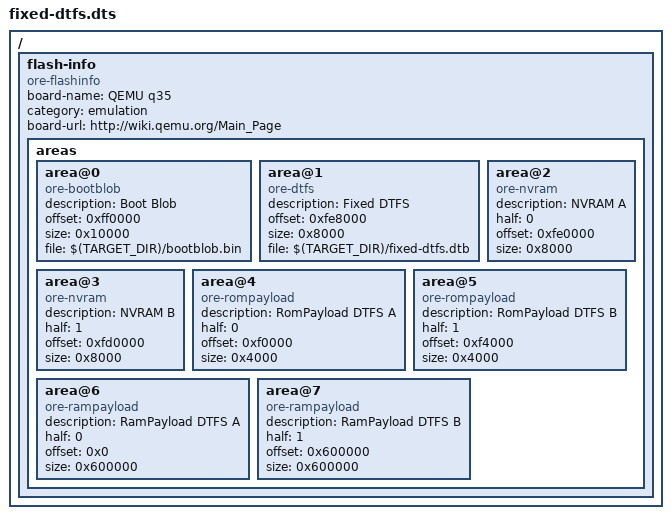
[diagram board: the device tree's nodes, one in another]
/dts-v1/;

/ {
    #address-cells = <1>;
    #size-cells = <1>;

    flash-info {
        compatible = "ore-flashinfo";
        board-name = "QEMU q35";
        category = "emulation";
        board-url = "http://wiki.qemu.org/Main_Page";
        areas {
            area@0 {
                description = "Boot Blob";
                compatible = "ore-bootblob";
                offset = <0xff0000>;
                size = <0x10000>;
                file = "$(TARGET_DIR)/bootblob.bin";
            };
            area@1 {
                description = "Fixed DTFS";
                compatible = "ore-dtfs";
                offset = <0xfe8000>;
                size = <0x8000>;
                file = "$(TARGET_DIR)/fixed-dtfs.dtb";
            };
            area@2 {
                description = "NVRAM A";
                compatible = "ore-nvram";
                half = <0>;
                offset = <0xfe0000>;
                size = <0x8000>;
            };
            area@3 {
                description = "NVRAM B";
                compatible = "ore-nvram";
                half = <1>;
                offset = <0xfd0000>;
                size = <0x8000>;
            };
            area@4 {
                description = "RomPayload DTFS A";
                compatible = "ore-rompayload";
                half = <0>;
                offset = <0xf0000>;
                size = <0x4000>;
            };
            area@5 {
                description = "RomPayload DTFS B";
                compatible = "ore-rompayload";
                half = <1>;
                offset = <0xf4000>;
                size = <0x4000>;
            };
            area@6 {
                description = "RamPayload DTFS A";
                compatible = "ore-rampayload";
                half = <0>;
                offset = <0x0>;
                size = <0x600000>;
            };
            area@7 {
                description = "RamPayload DTFS B";
                compatible = "ore-rampayload";
                half = <1>;
                offset = <0x600000>;
                size = <0x600000>;
            };
        };
    };
};
